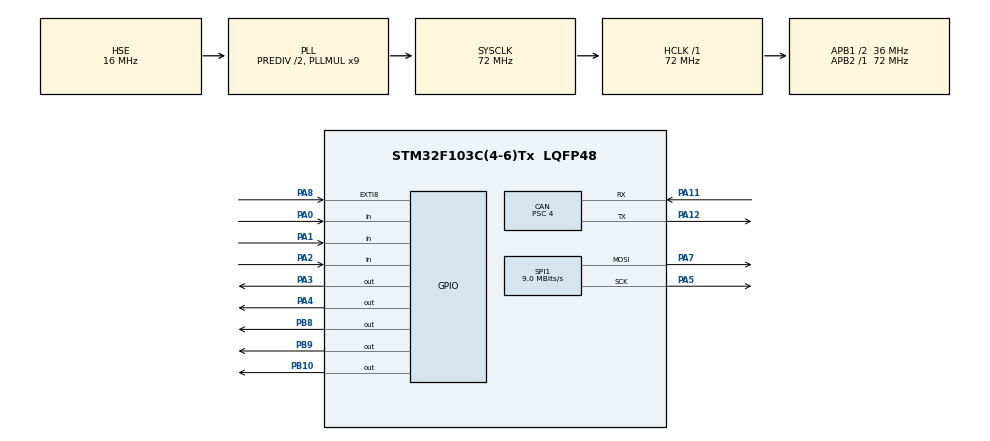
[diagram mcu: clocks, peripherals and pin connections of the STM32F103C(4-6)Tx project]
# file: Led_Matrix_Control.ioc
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CAN.BS1=CAN_BS1_11TQ
CAN.BS2=CAN_BS2_4TQ
CAN.CalculateBaudRate=562500
CAN.CalculateTimeBit=1777
CAN.CalculateTimeQuantum=111.11111111111111
CAN.Prescaler=4
CAN.SJW=CAN_SJW_4TQ
FREERTOS.HEAP_NUMBER=1
FREERTOS.INCLUDE_uxTaskPriorityGet=0
FREERTOS.INCLUDE_vTaskDelete=0
FREERTOS.INCLUDE_vTaskPrioritySet=0
FREERTOS.INCLUDE_vTaskSuspend=0
FREERTOS.MEMORY_ALLOCATION=1
FREERTOS.Tasks01=defaultTask,0,256,StartDefaultTask,Default,NULL,Static,defaultTaskBuffer,defaultTaskControlBlock
FREERTOS.configENABLE_BACKWARD_COMPATIBILITY=0
FREERTOS.configMINIMAL_STACK_SIZE=64
FREERTOS.configUSE_MUTEXES=0
FREERTOS.configUSE_NEWLIB_REENTRANT=1
FREERTOS.configUSE_TASK_NOTIFICATIONS=1
FREERTOS.copyHeapFile=0
Mcu.Family=STM32F1
Mcu.Name=STM32F103C(4-6)Tx
Mcu.Package=LQFP48
NVIC.CAN1_RX1_IRQn=true\:5\:0\:false\:false\:true\:true\:true\:true\:true
NVIC.CAN1_SCE_IRQn=true\:5\:0\:false\:false\:true\:true\:true\:true\:true
NVIC.PriorityGroup=NVIC_PRIORITYGROUP_4
NVIC.TIM1_UP_IRQn=true\:15\:0\:false\:false\:true\:false\:false\:true\:true
NVIC.TimeBase=TIM1_UP_IRQn
NVIC.TimeBaseIP=TIM1
NVIC.USB_HP_CAN1_TX_IRQn=true\:5\:0\:false\:false\:true\:true\:true\:true\:true
NVIC.USB_LP_CAN1_RX0_IRQn=true\:5\:0\:false\:false\:true\:true\:true\:true\:true
PA0-WKUP.Signal=GPIO_Input
PA1.Signal=GPIO_Input
PA10.Signal=USART1_RX
PA11.Mode=CAN_Activate
PA11.Signal=CAN_RX
PA12.Mode=CAN_Activate
PA12.Signal=CAN_TX
PA13.Mode=Serial_Wire
PA13.Signal=SYS_JTMS-SWDIO
PA14.Mode=Serial_Wire
PA14.Signal=SYS_JTCK-SWCLK
PA15.Signal=SYS_JTDI
PA2.Signal=GPIO_Input
PA3.PinState=GPIO_PIN_SET
PA3.Signal=GPIO_Output
PA4.PinState=GPIO_PIN_SET
PA4.Signal=GPIO_Output
PA5.Mode=TX_Only_Simplex_Unidirect_Master
PA5.Signal=SPI1_SCK
PA7.Mode=TX_Only_Simplex_Unidirect_Master
PA7.Signal=SPI1_MOSI
PA8.Signal=GPXTI8
PA9.Signal=USART1_TX
PB10.Signal=GPIO_Output
PB3.Signal=SYS_JTDO-TRACESWO
PB6.Signal=I2C1_SCL
PB7.Signal=I2C1_SDA
PB8.Signal=GPIO_Output
PB9.Signal=GPIO_Output
PD0-OSC_IN.Mode=HSE-External-Oscillator
PD0-OSC_IN.Signal=RCC_OSC_IN
PD1-OSC_OUT.Mode=HSE-External-Oscillator
PD1-OSC_OUT.Signal=RCC_OSC_OUT
ProjectManager.HeapSize=0x40
ProjectManager.StackSize=0x100
ProjectManager.TargetToolchain=CMake
RCC.AHBFreq_Value=72000000
RCC.APB1CLKDivider=RCC_HCLK_DIV2
RCC.APB1Freq_Value=36000000
RCC.APB1TimFreq_Value=72000000
RCC.APB2Freq_Value=72000000
RCC.APB2TimFreq_Value=72000000
RCC.HCLKFreq_Value=72000000
RCC.HSEDivPLL=RCC_HSE_PREDIV_DIV2
RCC.HSE_VALUE=16000000
RCC.PLLMUL=RCC_PLL_MUL9
RCC.PLLSourceVirtual=RCC_PLLSOURCE_HSE
RCC.SYSCLKFreq_VALUE=72000000
RCC.SYSCLKSource=RCC_SYSCLKSOURCE_PLLCLK
RCC.USBFreq_Value=72000000
SPI1.BaudRatePrescaler=SPI_BAUDRATEPRESCALER_8
SPI1.CalculateBaudRate=9.0 MBits/s
SPI1.Direction=SPI_DIRECTION_2LINES
SPI1.Mode=SPI_MODE_MASTER
SPI1.VirtualType=VM_MASTER
VP_FREERTOS_VS_CMSIS_V1.Mode=CMSIS_V1
VP_SYS_VS_tim1.Mode=TIM1
board=custom

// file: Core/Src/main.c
/* USER CODE BEGIN Header */
/**
  ******************************************************************************
  * @file           : main.c
  * @brief          : Main program body
  ******************************************************************************
  * @attention
  *
  * Copyright (c) 2025 STMicroelectronics.
  * All rights reserved.
  *
  * This software is licensed under terms that can be found in the LICENSE file
  * in the root directory of this software component.
  * If no LICENSE file comes with this software, it is provided AS-IS.
  *
  ******************************************************************************
  */
/* USER CODE END Header */
#include "main.h"
#include "cmsis_os.h"
#include "can.h"
#include "spi.h"
#include "gpio.h"

void SystemClock_Config(void);
void MX_FREERTOS_Init(void);

int main(void)
{

  /* MCU Configuration--------------------------------------------------------*/

  /* Reset of all peripherals, Initializes the Flash interface and the Systick. */
  HAL_Init();

  /* Configure the system clock */
  SystemClock_Config();

  /* Initialize all configured peripherals */
  MX_GPIO_Init();
  MX_CAN_Init();
  MX_SPI1_Init();

  /* Call init function for freertos objects (in cmsis_os2.c) */
  MX_FREERTOS_Init();

  /* Start scheduler */
  osKernelStart();

  /* We should never get here as control is now taken by the scheduler */

  /* Infinite loop */
  while (1)
  {

  }
}

void SystemClock_Config(void)
{
  RCC_OscInitTypeDef RCC_OscInitStruct = {0};
  RCC_ClkInitTypeDef RCC_ClkInitStruct = {0};

  /** Initializes the RCC Oscillators according to the specified parameters
  * in the RCC_OscInitTypeDef structure.
  */
  RCC_OscInitStruct.OscillatorType = RCC_OSCILLATORTYPE_HSE;
  RCC_OscInitStruct.HSEState = RCC_HSE_ON;
  RCC_OscInitStruct.HSEPredivValue = RCC_HSE_PREDIV_DIV2;
  RCC_OscInitStruct.HSIState = RCC_HSI_ON;
  RCC_OscInitStruct.PLL.PLLState = RCC_PLL_ON;
  RCC_OscInitStruct.PLL.PLLSource = RCC_PLLSOURCE_HSE;
  RCC_OscInitStruct.PLL.PLLMUL = RCC_PLL_MUL9;
  if (HAL_RCC_OscConfig(&RCC_OscInitStruct) != HAL_OK)
  {
    Error_Handler();
  }

  /** Initializes the CPU, AHB and APB buses clocks
  */
  RCC_ClkInitStruct.ClockType = RCC_CLOCKTYPE_HCLK|RCC_CLOCKTYPE_SYSCLK
                              |RCC_CLOCKTYPE_PCLK1|RCC_CLOCKTYPE_PCLK2;
  RCC_ClkInitStruct.SYSCLKSource = RCC_SYSCLKSOURCE_PLLCLK;
  RCC_ClkInitStruct.AHBCLKDivider = RCC_SYSCLK_DIV1;
  RCC_ClkInitStruct.APB1CLKDivider = RCC_HCLK_DIV2;
  RCC_ClkInitStruct.APB2CLKDivider = RCC_HCLK_DIV1;

  if (HAL_RCC_ClockConfig(&RCC_ClkInitStruct, FLASH_LATENCY_2) != HAL_OK)
  {
    Error_Handler();
  }
}

void HAL_TIM_PeriodElapsedCallback(TIM_HandleTypeDef *htim)
{
  if (htim->Instance == TIM1)
  {
    HAL_IncTick();
  }
}

void Error_Handler(void)
{
  __disable_irq();
  while (1)
  {
  }
}

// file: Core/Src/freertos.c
/* USER CODE BEGIN Header */
/**
  ******************************************************************************
  * File Name          : freertos.c
  * Description        : Code for freertos applications
  ******************************************************************************
  * @attention
  *
  * Copyright (c) 2025 STMicroelectronics.
  * All rights reserved.
  *
  * This software is licensed under terms that can be found in the LICENSE file
  * in the root directory of this software component.
  * If no LICENSE file comes with this software, it is provided AS-IS.
  *
  ******************************************************************************
  */
/* USER CODE END Header */

#include "FreeRTOS.h"
#include "task.h"
#include "main.h"
#include "cmsis_os.h"

osThreadId defaultTaskHandle;
uint32_t defaultTaskBuffer[ 256 ];
osStaticThreadDef_t defaultTaskControlBlock;

void StartDefaultTask(void const * argument);

void MX_FREERTOS_Init(void); /* (MISRA C 2004 rule 8.1) */

/* GetIdleTaskMemory prototype (linked to static allocation support) */
void vApplicationGetIdleTaskMemory( StaticTask_t **ppxIdleTaskTCBBuffer, StackType_t **ppxIdleTaskStackBuffer, uint32_t *pulIdleTaskStackSize );

/* USER CODE BEGIN GET_IDLE_TASK_MEMORY */
static StaticTask_t xIdleTaskTCBBuffer;
static StackType_t xIdleStack[configMINIMAL_STACK_SIZE];

void vApplicationGetIdleTaskMemory( StaticTask_t **ppxIdleTaskTCBBuffer, StackType_t **ppxIdleTaskStackBuffer, uint32_t *pulIdleTaskStackSize )
{
  *ppxIdleTaskTCBBuffer = &xIdleTaskTCBBuffer;
  *ppxIdleTaskStackBuffer = &xIdleStack[0];
  *pulIdleTaskStackSize = configMINIMAL_STACK_SIZE;
  /* place for user code */
}
/* USER CODE END GET_IDLE_TASK_MEMORY */

void MX_FREERTOS_Init(void) {

  /* Create the thread(s) */
  /* definition and creation of defaultTask */
  osThreadStaticDef(defaultTask, StartDefaultTask, osPriorityNormal, 0, 256, defaultTaskBuffer, &defaultTaskControlBlock);
  defaultTaskHandle = osThreadCreate(osThread(defaultTask), NULL);

}

/* USER CODE BEGIN Header_StartDefaultTask */

extern void Main_cycle(void);

/**
 * @brief  Function implementing the defaultTask thread.
 * @param  argument: Not used
 * @retval None
 */
/* USER CODE END Header_StartDefaultTask */
void StartDefaultTask(void const * argument)
{
  /* USER CODE BEGIN StartDefaultTask */

  Main_cycle();

  /* Infinite loop */
  for(;;)
  {
    osDelay(1);
  }
  /* USER CODE END StartDefaultTask */
}
